VERSION ""

NS_ :

BS_:

BU_:

BO_ 3221225472 VECTOR__INDEPENDENT_SIG_MSG: 0 Vector__XXX
 SG_ station_solenoid_2_status : 0|1@1+ (1,0) [0|1] "" Vector__XXX
 SG_ station_solenoid_1_status : 0|1@1+ (1,0) [0|1] "" Vector__XXX
 SG_ gun_lock_request : 0|2@1+ (1,0) [0|3] "" Vector__XXX
 SG_ earth_life_open : 0|1@1+ (1,0) [0|1] "" Vector__XXX
 SG_ ccs_charge_detect : 0|1@1+ (1,0) [0|1] "" Vector__XXX
 SG_ string_data_no : 0|8@1+ (1,0) [0|255] "" Vector__XXX
 SG_ temp_imbalance : 0|16@1+ (0.01,-100) [-100|555.35] "" Vector__XXX
 SG_ pack_voltage_imbalance : 0|16@1+ (0.0001,0) [0|6.5535] "" Vector__XXX

BO_ 1028 afe_config_details: 8 Vector__XXX
 SG_ config_afe_gpo9 : 23|1@1+ (1,0) [0|1] "" Vector__XXX
 SG_ config_afe_gpo8 : 22|1@1+ (1,0) [0|1] "" Vector__XXX
 SG_ config_afe_gpo7 : 21|1@1+ (1,0) [0|1] "" Vector__XXX
 SG_ config_afe_gpo6 : 20|1@1+ (1,0) [0|1] "" Vector__XXX
 SG_ config_afe_gpo5 : 19|1@1+ (1,0) [0|1] "" Vector__XXX
 SG_ config_afe_gpo4 : 18|1@1+ (1,0) [0|1] "" Vector__XXX
 SG_ config_afe_gpo3 : 17|1@1+ (1,0) [0|1] "" Vector__XXX
 SG_ config_afe_gpo2 : 16|1@1+ (1,0) [0|1] "" Vector__XXX
 SG_ config_afe_gpo1 : 15|1@1+ (1,0) [0|1] "" Vector__XXX
 SG_ config_afe_gpo0 : 14|1@1+ (1,0) [0|1] "" Vector__XXX
 SG_ config_afe_mute_st : 13|1@1+ (1,0) [0|1] "" Vector__XXX
 SG_ config_afe_com_break : 12|1@1+ (1,0) [0|1] "" Vector__XXX
 SG_ config_afe_tmodchk : 11|1@1+ (1,0) [0|1] "" Vector__XXX
 SG_ config_afe_nvm_med : 10|1@1+ (1,0) [0|1] "" Vector__XXX
 SG_ config_afe_nvm_ed : 9|1@1+ (1,0) [0|1] "" Vector__XXX
 SG_ config_afe_thsd : 8|1@1+ (1,0) [0|1] "" Vector__XXX
 SG_ config_afe_supply_ov_uv : 7|1@1+ (1,0) [0|1] "" Vector__XXX
 SG_ config_afe_ed : 6|1@1+ (1,0) [0|1] "" Vector__XXX
 SG_ config_afe_ocs : 5|1@1+ (1,0) [0|1] "" Vector__XXX
 SG_ config_afe_ocf : 4|1@1+ (1,0) [0|1] "" Vector__XXX
 SG_ config_afe_cth : 1|3@1+ (1,0) [0|7] "" Vector__XXX
 SG_ config_afe_refon : 0|1@1+ (1,0) [0|1] "" Vector__XXX

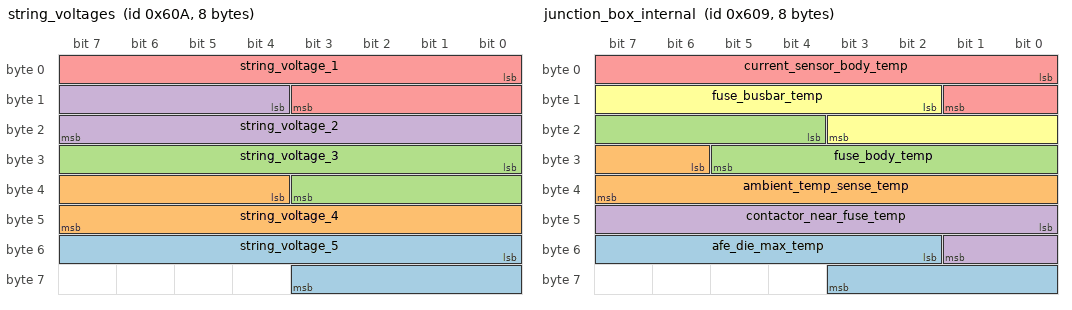
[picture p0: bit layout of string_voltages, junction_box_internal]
BO_ 1546 string_voltages: 8 Vector__XXX
 SG_ string_voltage_5 : 48|12@1+ (0.2,0) [0|819] "" Vector__XXX
 SG_ string_voltage_4 : 36|12@1+ (0.2,0) [0|819] "" Vector__XXX
 SG_ string_voltage_3 : 24|12@1+ (0.2,0) [0|819] "" Vector__XXX
 SG_ string_voltage_2 : 12|12@1+ (0.2,0) [0|819] "" Vector__XXX
 SG_ string_voltage_1 : 0|12@1+ (0.2,0) [0|819] "" Vector__XXX

BO_ 1667 subpack_unique_key: 8 Vector__XXX
 SG_ subpack_unique_key : 0|64@1+ (1,0) [0|1.84467440737096E+019] "" Vector__XXX

BO_ 1664 battery_unique_key: 8 Vector__XXX
 SG_ battery_unique_key : 0|64@1+ (1,0) [0|1.84467440737096E+019] "" Vector__XXX

BO_ 1545 junction_box_internal: 8 Vector__XXX
 SG_ afe_die_max_temp : 50|10@1+ (1,-200) [-200|823] "" Vector__XXX
 SG_ ambient_temp_sense_temp : 30|10@1+ (1,-200) [-200|823] "" Vector__XXX
 SG_ fuse_body_temp : 20|10@1+ (1,-200) [-200|823] "" Vector__XXX
 SG_ contactor_near_fuse_temp : 40|10@1+ (1,-200) [-200|823] "" Vector__XXX
 SG_ current_sensor_body_temp : 0|10@1+ (1,-200) [-200|823] "" Vector__XXX
 SG_ fuse_busbar_temp : 10|10@1+ (1,-200) [-200|823] "" Vector__XXX

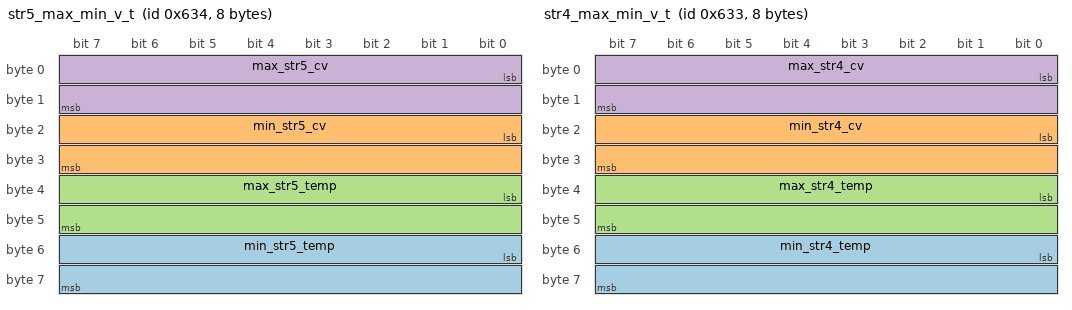
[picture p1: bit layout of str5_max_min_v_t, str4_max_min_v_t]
BO_ 1588 str5_max_min_v_t: 8 Vector__XXX
 SG_ min_str5_temp : 48|16@1+ (0.01,-100) [-100|555.35] "C" Vector__XXX
 SG_ min_str5_cv : 16|16@1+ (0.0001,0) [0|6.5535] "V" Vector__XXX
 SG_ max_str5_temp : 32|16@1+ (0.01,-100) [-100|555.35] "C" Vector__XXX
 SG_ max_str5_cv : 0|16@1+ (0.0001,0) [0|6.5535] "V" Vector__XXX

BO_ 1587 str4_max_min_v_t: 8 Vector__XXX
 SG_ min_str4_temp : 48|16@1+ (0.01,-100) [-100|555.35] "C" Vector__XXX
 SG_ min_str4_cv : 16|16@1+ (0.0001,0) [0|6.5535] "V" Vector__XXX
 SG_ max_str4_temp : 32|16@1+ (0.01,-100) [-100|555.35] "C" Vector__XXX
 SG_ max_str4_cv : 0|16@1+ (0.0001,0) [0|6.5535] "V" Vector__XXX

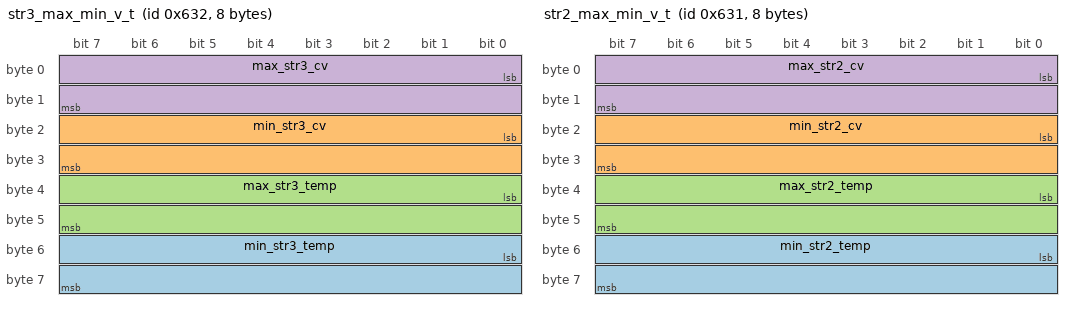
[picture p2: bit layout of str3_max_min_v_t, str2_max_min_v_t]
BO_ 1586 str3_max_min_v_t: 8 Vector__XXX
 SG_ min_str3_temp : 48|16@1+ (0.01,-100) [-100|555.35] "C" Vector__XXX
 SG_ min_str3_cv : 16|16@1+ (0.0001,0) [0|6.5535] "V" Vector__XXX
 SG_ max_str3_temp : 32|16@1+ (0.01,-100) [-100|555.35] "C" Vector__XXX
 SG_ max_str3_cv : 0|16@1+ (0.0001,0) [0|6.5535] "V" Vector__XXX

BO_ 1585 str2_max_min_v_t: 8 Vector__XXX
 SG_ min_str2_temp : 48|16@1+ (0.01,-100) [-100|555.35] "C" Vector__XXX
 SG_ min_str2_cv : 16|16@1+ (0.0001,0) [0|6.5535] "V" Vector__XXX
 SG_ max_str2_temp : 32|16@1+ (0.01,-100) [-100|555.35] "C" Vector__XXX
 SG_ max_str2_cv : 0|16@1+ (0.0001,0) [0|6.5535] "V" Vector__XXX

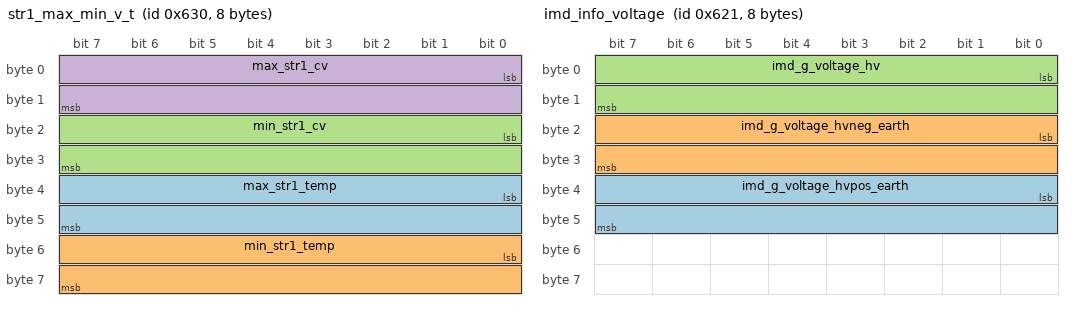
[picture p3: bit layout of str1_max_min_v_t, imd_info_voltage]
BO_ 1584 str1_max_min_v_t: 8 Vector__XXX
 SG_ max_str1_temp : 32|16@1+ (0.01,-100) [-100|555.35] "C" Vector__XXX
 SG_ min_str1_temp : 48|16@1+ (0.01,-100) [-100|555.35] "C" Vector__XXX
 SG_ min_str1_cv : 16|16@1+ (0.0001,0) [0|6.5535] "V" Vector__XXX
 SG_ max_str1_cv : 0|16@1+ (0.0001,0) [0|6.5535] "V" Vector__XXX

BO_ 1569 imd_info_voltage: 8 Vector__XXX
 SG_ imd_g_voltage_hvpos_earth : 32|16@1+ (0.1,-1000) [-1000|5553.5] "" Vector__XXX
 SG_ imd_g_voltage_hvneg_earth : 16|16@1+ (0.1,-1000) [-1000|5553.5] "" Vector__XXX
 SG_ imd_g_voltage_hv : 0|16@1+ (0.1,-1000) [-1000|5553.5] "" Vector__XXX

BO_ 1568 imd_iso_alarm_details: 8 Vector__XXX
 SG_ imd_g_warn_alarm_bit_15 : 63|1@1+ (1,0) [0|1] "" Vector__XXX
 SG_ imd_g_warn_alarm_bit_14 : 62|1@1+ (1,0) [0|1] "" Vector__XXX
 SG_ imd_g_warn_alarm_bit_13 : 61|1@1+ (1,0) [0|1] "" Vector__XXX
 SG_ imd_g_warn_alarm_bit_12 : 60|1@1+ (1,0) [0|1] "" Vector__XXX
 SG_ imd_g_warn_alarm_bit_11 : 59|1@1+ (1,0) [0|1] "" Vector__XXX
 SG_ imd_g_warn_alarm_bit_10 : 58|1@1+ (1,0) [0|1] "" Vector__XXX
 SG_ imd_g_warn_alarm_bit_09 : 57|1@1+ (1,0) [0|1] "" Vector__XXX
 SG_ imd_g_warn_alarm_bit_08 : 56|1@1+ (1,0) [0|1] "" Vector__XXX
 SG_ imd_g_warn_alarm_bit_07 : 55|1@1+ (1,0) [0|1] "" Vector__XXX
 SG_ imd_g_warn_alarm_bit_06 : 54|1@1+ (1,0) [0|1] "" Vector__XXX
 SG_ imd_g_warn_alarm_bit_05 : 53|1@1+ (1,0) [0|1] "" Vector__XXX
 SG_ imd_g_warn_alarm_bit_04 : 52|1@1+ (1,0) [0|1] "" Vector__XXX
 SG_ imd_g_warn_alarm_bit_03 : 51|1@1+ (1,0) [0|1] "" Vector__XXX
 SG_ imd_g_warn_alarm_bit_02 : 50|1@1+ (1,0) [0|1] "" Vector__XXX
 SG_ imd_g_warn_alarm_bit_01 : 49|1@1+ (1,0) [0|1] "" Vector__XXX
 SG_ imd_g_warn_alarm_bit_00 : 48|1@1+ (1,0) [0|1] "" Vector__XXX
 SG_ imd_g_iso_r_iso_original : 32|16@1+ (1,0) [0|65535] "" Vector__XXX
 SG_ imd_g_iso_r_iso_pos : 16|16@1+ (1,0) [0|65535] "" Vector__XXX
 SG_ imd_g_iso_r_iso_neg : 0|16@1+ (1,0) [0|65535] "" Vector__XXX

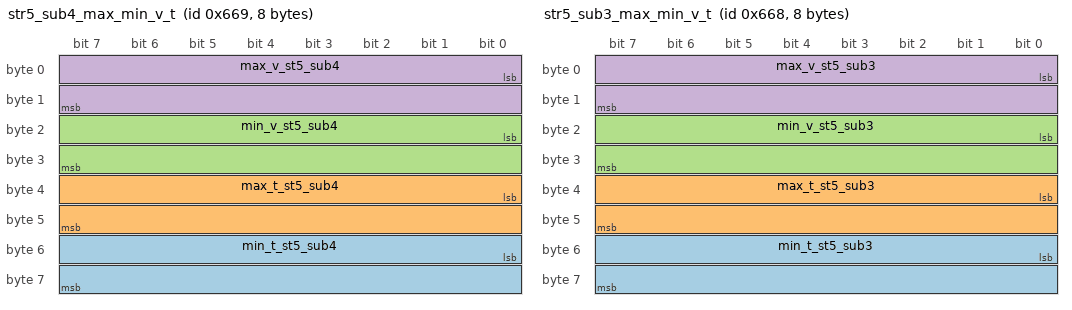
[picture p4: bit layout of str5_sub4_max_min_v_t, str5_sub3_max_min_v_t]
BO_ 1641 str5_sub4_max_min_v_t: 8 Vector__XXX
 SG_ min_t_st5_sub4 : 48|16@1+ (0.01,-100) [-100|555.35] "C" Vector__XXX
 SG_ max_t_st5_sub4 : 32|16@1+ (0.01,-100) [-100|555.35] "C" Vector__XXX
 SG_ min_v_st5_sub4 : 16|16@1+ (0.0001,0) [0|6.5535] "V" Vector__XXX
 SG_ max_v_st5_sub4 : 0|16@1+ (0.0001,0) [0|6.5535] "V" Vector__XXX

BO_ 1640 str5_sub3_max_min_v_t: 8 Vector__XXX
 SG_ min_t_st5_sub3 : 48|16@1+ (0.01,-100) [-100|555.35] "C" Vector__XXX
 SG_ max_t_st5_sub3 : 32|16@1+ (0.01,-100) [-100|555.35] "C" Vector__XXX
 SG_ min_v_st5_sub3 : 16|16@1+ (0.0001,0) [0|6.5535] "V" Vector__XXX
 SG_ max_v_st5_sub3 : 0|16@1+ (0.0001,0) [0|6.5535] "V" Vector__XXX

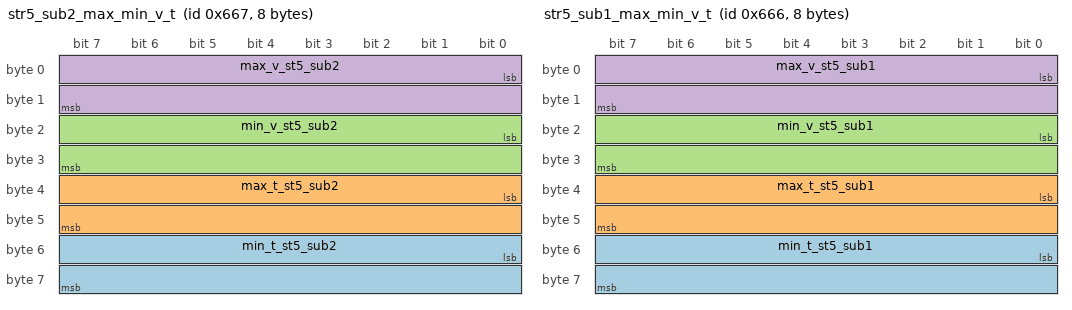
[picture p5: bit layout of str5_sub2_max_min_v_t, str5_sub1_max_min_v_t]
BO_ 1639 str5_sub2_max_min_v_t: 8 Vector__XXX
 SG_ min_t_st5_sub2 : 48|16@1+ (0.01,-100) [-100|555.35] "C" Vector__XXX
 SG_ max_t_st5_sub2 : 32|16@1+ (0.01,-100) [-100|555.35] "C" Vector__XXX
 SG_ min_v_st5_sub2 : 16|16@1+ (0.0001,0) [0|6.5535] "V" Vector__XXX
 SG_ max_v_st5_sub2 : 0|16@1+ (0.0001,0) [0|6.5535] "V" Vector__XXX

BO_ 1638 str5_sub1_max_min_v_t: 8 Vector__XXX
 SG_ min_t_st5_sub1 : 48|16@1+ (0.01,-100) [-100|555.35] "C" Vector__XXX
 SG_ max_t_st5_sub1 : 32|16@1+ (0.01,-100) [-100|555.35] "C" Vector__XXX
 SG_ min_v_st5_sub1 : 16|16@1+ (0.0001,0) [0|6.5535] "V" Vector__XXX
 SG_ max_v_st5_sub1 : 0|16@1+ (0.0001,0) [0|6.5535] "V" Vector__XXX

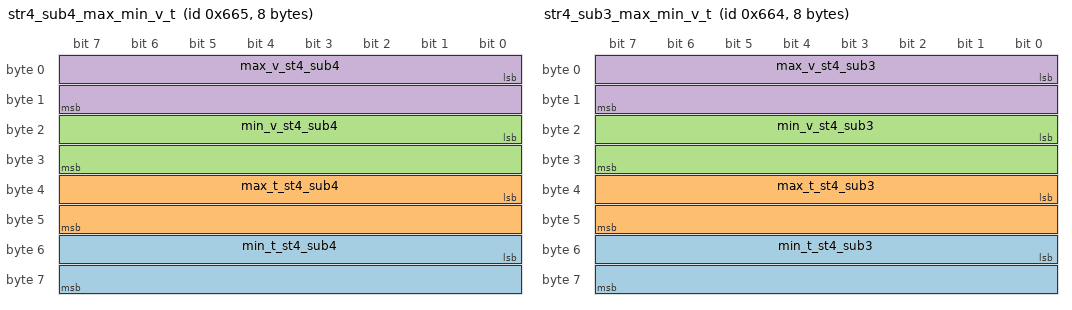
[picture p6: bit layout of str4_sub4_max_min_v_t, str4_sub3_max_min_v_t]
BO_ 1637 str4_sub4_max_min_v_t: 8 Vector__XXX
 SG_ min_t_st4_sub4 : 48|16@1+ (0.01,-100) [-100|555.35] "C" Vector__XXX
 SG_ max_t_st4_sub4 : 32|16@1+ (0.01,-100) [-100|555.35] "C" Vector__XXX
 SG_ min_v_st4_sub4 : 16|16@1+ (0.0001,0) [0|6.5535] "V" Vector__XXX
 SG_ max_v_st4_sub4 : 0|16@1+ (0.0001,0) [0|6.5535] "V" Vector__XXX

BO_ 1636 str4_sub3_max_min_v_t: 8 Vector__XXX
 SG_ min_t_st4_sub3 : 48|16@1+ (0.01,-100) [-100|555.35] "C" Vector__XXX
 SG_ max_t_st4_sub3 : 32|16@1+ (0.01,-100) [-100|555.35] "C" Vector__XXX
 SG_ min_v_st4_sub3 : 16|16@1+ (0.0001,0) [0|6.5535] "V" Vector__XXX
 SG_ max_v_st4_sub3 : 0|16@1+ (0.0001,0) [0|6.5535] "V" Vector__XXX

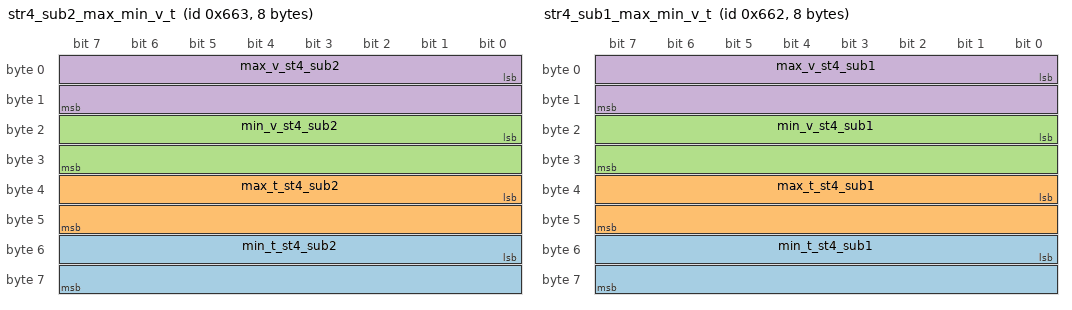
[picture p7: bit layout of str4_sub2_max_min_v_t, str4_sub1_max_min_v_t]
BO_ 1635 str4_sub2_max_min_v_t: 8 Vector__XXX
 SG_ min_t_st4_sub2 : 48|16@1+ (0.01,-100) [-100|555.35] "C" Vector__XXX
 SG_ max_t_st4_sub2 : 32|16@1+ (0.01,-100) [-100|555.35] "C" Vector__XXX
 SG_ min_v_st4_sub2 : 16|16@1+ (0.0001,0) [0|6.5535] "V" Vector__XXX
 SG_ max_v_st4_sub2 : 0|16@1+ (0.0001,0) [0|6.5535] "V" Vector__XXX

BO_ 1634 str4_sub1_max_min_v_t: 8 Vector__XXX
 SG_ min_t_st4_sub1 : 48|16@1+ (0.01,-100) [-100|555.35] "C" Vector__XXX
 SG_ max_t_st4_sub1 : 32|16@1+ (0.01,-100) [-100|555.35] "C" Vector__XXX
 SG_ min_v_st4_sub1 : 16|16@1+ (0.0001,0) [0|6.5535] "V" Vector__XXX
 SG_ max_v_st4_sub1 : 0|16@1+ (0.0001,0) [0|6.5535] "V" Vector__XXX

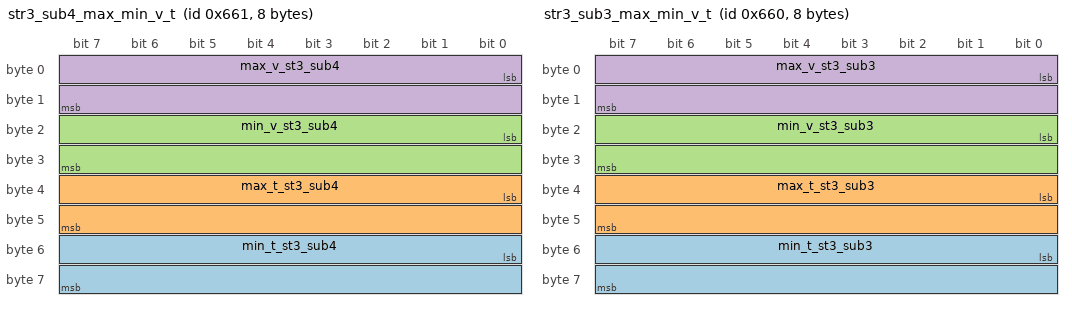
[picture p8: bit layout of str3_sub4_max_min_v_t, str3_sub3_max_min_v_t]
BO_ 1633 str3_sub4_max_min_v_t: 8 Vector__XXX
 SG_ min_t_st3_sub4 : 48|16@1+ (0.01,-100) [-100|555.35] "C" Vector__XXX
 SG_ max_t_st3_sub4 : 32|16@1+ (0.01,-100) [-100|555.35] "C" Vector__XXX
 SG_ min_v_st3_sub4 : 16|16@1+ (0.0001,0) [0|6.5535] "V" Vector__XXX
 SG_ max_v_st3_sub4 : 0|16@1+ (0.0001,0) [0|6.5535] "V" Vector__XXX

BO_ 1632 str3_sub3_max_min_v_t: 8 Vector__XXX
 SG_ min_t_st3_sub3 : 48|16@1+ (0.01,-100) [-100|555.35] "C" Vector__XXX
 SG_ max_t_st3_sub3 : 32|16@1+ (0.01,-100) [-100|555.35] "C" Vector__XXX
 SG_ min_v_st3_sub3 : 16|16@1+ (0.0001,0) [0|6.5535] "V" Vector__XXX
 SG_ max_v_st3_sub3 : 0|16@1+ (0.0001,0) [0|6.5535] "V" Vector__XXX

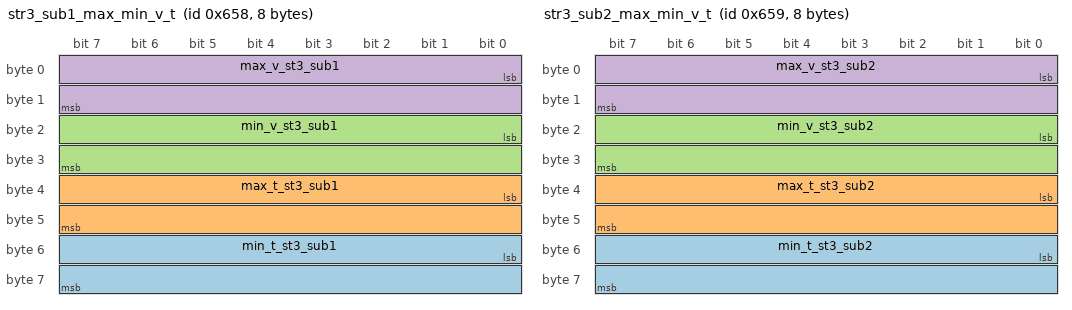
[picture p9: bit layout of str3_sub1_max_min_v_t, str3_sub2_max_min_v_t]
BO_ 1624 str3_sub1_max_min_v_t: 8 Vector__XXX
 SG_ min_t_st3_sub1 : 48|16@1+ (0.01,-100) [-100|555.35] "C" Vector__XXX
 SG_ max_t_st3_sub1 : 32|16@1+ (0.01,-100) [-100|555.35] "C" Vector__XXX
 SG_ min_v_st3_sub1 : 16|16@1+ (0.0001,0) [0|6.5535] "V" Vector__XXX
 SG_ max_v_st3_sub1 : 0|16@1+ (0.0001,0) [0|6.5535] "V" Vector__XXX

BO_ 1625 str3_sub2_max_min_v_t: 8 Vector__XXX
 SG_ min_t_st3_sub2 : 48|16@1+ (0.01,-100) [-100|555.35] "C" Vector__XXX
 SG_ max_t_st3_sub2 : 32|16@1+ (0.01,-100) [-100|555.35] "C" Vector__XXX
 SG_ min_v_st3_sub2 : 16|16@1+ (0.0001,0) [0|6.5535] "V" Vector__XXX
 SG_ max_v_st3_sub2 : 0|16@1+ (0.0001,0) [0|6.5535] "V" Vector__XXX

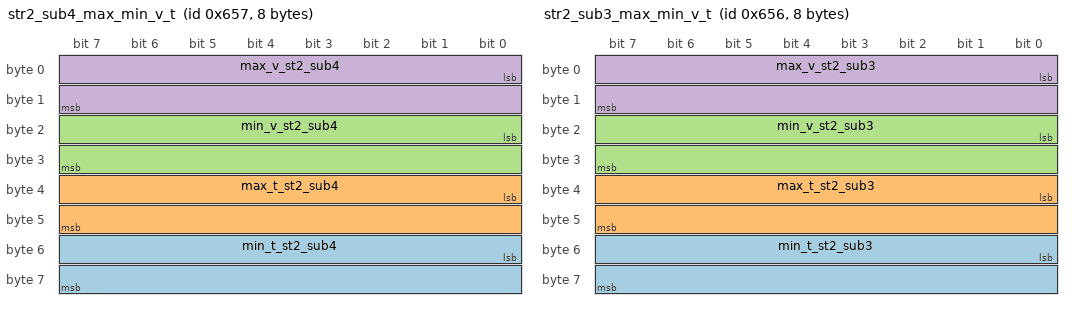
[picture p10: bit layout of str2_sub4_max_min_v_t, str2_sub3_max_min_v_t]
BO_ 1623 str2_sub4_max_min_v_t: 8 Vector__XXX
 SG_ min_t_st2_sub4 : 48|16@1+ (0.01,-100) [-100|555.35] "C" Vector__XXX
 SG_ max_t_st2_sub4 : 32|16@1+ (0.01,-100) [-100|555.35] "C" Vector__XXX
 SG_ min_v_st2_sub4 : 16|16@1+ (0.0001,0) [0|6.5535] "V" Vector__XXX
 SG_ max_v_st2_sub4 : 0|16@1+ (0.0001,0) [0|6.5535] "V" Vector__XXX

BO_ 1622 str2_sub3_max_min_v_t: 8 Vector__XXX
 SG_ min_t_st2_sub3 : 48|16@1+ (0.01,-100) [-100|555.35] "C" Vector__XXX
 SG_ max_t_st2_sub3 : 32|16@1+ (0.01,-100) [-100|555.35] "C" Vector__XXX
 SG_ min_v_st2_sub3 : 16|16@1+ (0.0001,0) [0|6.5535] "V" Vector__XXX
 SG_ max_v_st2_sub3 : 0|16@1+ (0.0001,0) [0|6.5535] "V" Vector__XXX

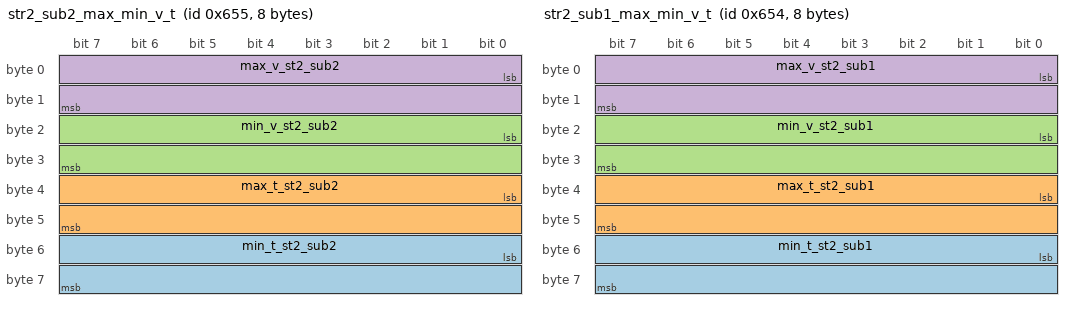
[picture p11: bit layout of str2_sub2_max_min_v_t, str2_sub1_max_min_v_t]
BO_ 1621 str2_sub2_max_min_v_t: 8 Vector__XXX
 SG_ min_t_st2_sub2 : 48|16@1+ (0.01,-100) [-100|555.35] "C" Vector__XXX
 SG_ max_t_st2_sub2 : 32|16@1+ (0.01,-100) [-100|555.35] "C" Vector__XXX
 SG_ min_v_st2_sub2 : 16|16@1+ (0.0001,0) [0|6.5535] "V" Vector__XXX
 SG_ max_v_st2_sub2 : 0|16@1+ (0.0001,0) [0|6.5535] "V" Vector__XXX

BO_ 1620 str2_sub1_max_min_v_t: 8 Vector__XXX
 SG_ min_t_st2_sub1 : 48|16@1+ (0.01,-100) [-100|555.35] "C" Vector__XXX
 SG_ max_t_st2_sub1 : 32|16@1+ (0.01,-100) [-100|555.35] "C" Vector__XXX
 SG_ min_v_st2_sub1 : 16|16@1+ (0.0001,0) [0|6.5535] "V" Vector__XXX
 SG_ max_v_st2_sub1 : 0|16@1+ (0.0001,0) [0|6.5535] "V" Vector__XXX

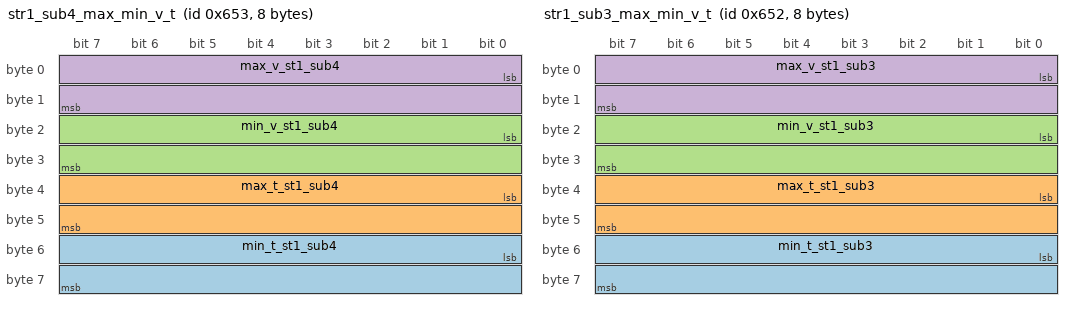
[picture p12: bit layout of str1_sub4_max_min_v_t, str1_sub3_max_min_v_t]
BO_ 1619 str1_sub4_max_min_v_t: 8 Vector__XXX
 SG_ min_t_st1_sub4 : 48|16@1+ (0.01,-100) [-100|555.35] "C" Vector__XXX
 SG_ max_t_st1_sub4 : 32|16@1+ (0.01,-100) [-100|555.35] "C" Vector__XXX
 SG_ min_v_st1_sub4 : 16|16@1+ (0.0001,0) [0|6.5535] "V" Vector__XXX
 SG_ max_v_st1_sub4 : 0|16@1+ (0.0001,0) [0|6.5535] "V" Vector__XXX

BO_ 1618 str1_sub3_max_min_v_t: 8 Vector__XXX
 SG_ min_t_st1_sub3 : 48|16@1+ (0.01,-100) [-100|555.35] "C" Vector__XXX
 SG_ max_t_st1_sub3 : 32|16@1+ (0.01,-100) [-100|555.35] "C" Vector__XXX
 SG_ min_v_st1_sub3 : 16|16@1+ (0.0001,0) [0|6.5535] "V" Vector__XXX
 SG_ max_v_st1_sub3 : 0|16@1+ (0.0001,0) [0|6.5535] "V" Vector__XXX

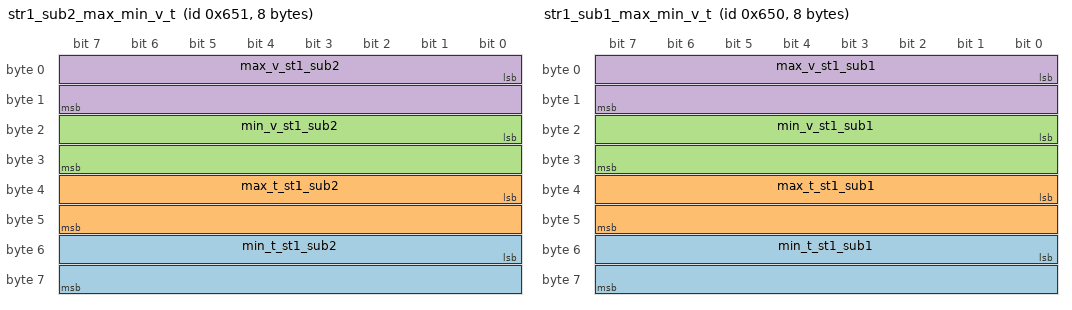
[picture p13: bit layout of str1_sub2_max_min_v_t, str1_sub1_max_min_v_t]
BO_ 1617 str1_sub2_max_min_v_t: 8 Vector__XXX
 SG_ min_t_st1_sub2 : 48|16@1+ (0.01,-100) [-100|555.35] "C" Vector__XXX
 SG_ max_t_st1_sub2 : 32|16@1+ (0.01,-100) [-100|555.35] "C" Vector__XXX
 SG_ min_v_st1_sub2 : 16|16@1+ (0.0001,0) [0|6.5535] "V" Vector__XXX
 SG_ max_v_st1_sub2 : 0|16@1+ (0.0001,0) [0|6.5535] "V" Vector__XXX

BO_ 1616 str1_sub1_max_min_v_t: 8 Vector__XXX
 SG_ min_t_st1_sub1 : 48|16@1+ (0.01,-100) [-100|555.35] "C" Vector__XXX
 SG_ max_t_st1_sub1 : 32|16@1+ (0.01,-100) [-100|555.35] "C" Vector__XXX
 SG_ min_v_st1_sub1 : 16|16@1+ (0.0001,0) [0|6.5535] "V" Vector__XXX
 SG_ max_v_st1_sub1 : 0|16@1+ (0.0001,0) [0|6.5535] "V" Vector__XXX

BO_ 336 station_heartbeat: 8 Vector__XXX
 SG_ station_unique_id : 0|32@1+ (1,0) [0|4294967295] "" Vector__XXX
 SG_ station_hw_version : 48|16@1+ (1,0) [0|65535] "" Vector__XXX
 SG_ station_fw_version : 32|16@1+ (1,0) [0|65535] "" Vector__XXX

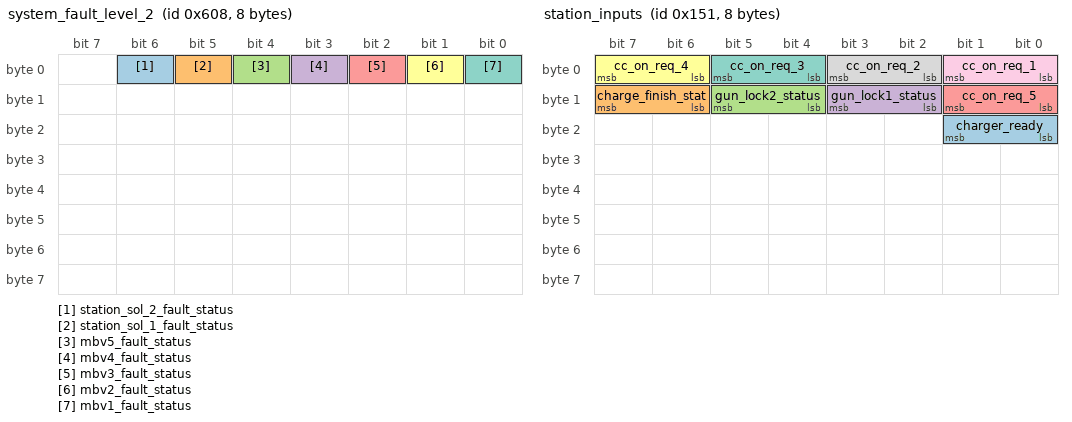
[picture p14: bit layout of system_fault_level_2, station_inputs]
BO_ 1544 system_fault_level_2: 8 Vector__XXX
 SG_ station_sol_2_fault_status : 6|1@1+ (1,0) [0|1] "" Vector__XXX
 SG_ station_sol_1_fault_status : 5|1@1+ (1,0) [0|1] "" Vector__XXX
 SG_ mbv5_fault_status : 4|1@1+ (1,0) [0|1] "" Vector__XXX
 SG_ mbv4_fault_status : 3|1@1+ (1,0) [0|1] "" Vector__XXX
 SG_ mbv3_fault_status : 2|1@1+ (1,0) [0|1] "" Vector__XXX
 SG_ mbv2_fault_status : 1|1@1+ (1,0) [0|1] "" Vector__XXX
 SG_ mbv1_fault_status : 0|1@1+ (1,0) [0|1] "" Vector__XXX

BO_ 339 override_details: 8 Vector__XXX
 SG_ override_status : 24|8@1+ (1,0) [0|0] "" Vector__XXX
 SG_ override_string_no : 16|8@1+ (1,0) [0|255] "" Vector__XXX
 SG_ override_data : 0|16@1+ (1,0) [0|65535] "" Vector__XXX

BO_ 337 station_inputs: 8 Vector__XXX
 SG_ charger_ready : 16|2@1+ (1,0) [0|3] "" Vector__XXX
 SG_ charge_finish_stat : 14|2@1+ (1,0) [0|3] "" Vector__XXX
 SG_ gun_lock2_status : 12|2@1+ (1,0) [0|3] "" Vector__XXX
 SG_ gun_lock1_status : 10|2@1+ (1,0) [0|3] "" Vector__XXX
 SG_ cc_on_req_5 : 8|2@1+ (1,0) [0|3] "" Vector__XXX
 SG_ cc_on_req_4 : 6|2@1+ (1,0) [0|3] "" Vector__XXX
 SG_ cc_on_req_3 : 4|2@1+ (1,0) [0|3] "" Vector__XXX
 SG_ cc_on_req_2 : 2|2@1+ (1,0) [0|3] "" Vector__XXX
 SG_ cc_on_req_1 : 0|2@1+ (1,0) [0|3] "" Vector__XXX

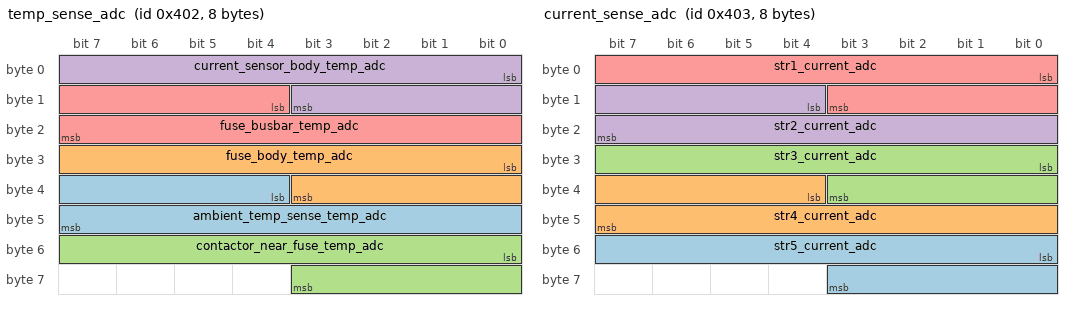
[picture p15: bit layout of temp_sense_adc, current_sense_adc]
BO_ 1026 temp_sense_adc: 8 Vector__XXX
 SG_ ambient_temp_sense_temp_adc : 36|12@1+ (1,0) [0|4095] "" Vector__XXX
 SG_ fuse_body_temp_adc : 24|12@1+ (1,0) [0|4095] "" Vector__XXX
 SG_ contactor_near_fuse_temp_adc : 48|12@1+ (1,0) [0|4095] "" Vector__XXX
 SG_ current_sensor_body_temp_adc : 0|12@1+ (1,0) [0|4095] "" Vector__XXX
 SG_ fuse_busbar_temp_adc : 12|12@1+ (1,0) [0|4095] "" Vector__XXX

BO_ 1027 current_sense_adc: 8 Vector__XXX
 SG_ str5_current_adc : 48|12@1+ (1,0) [0|4095] "" Vector__XXX
 SG_ str4_current_adc : 36|12@1+ (1,0) [0|4095] "" Vector__XXX
 SG_ str3_current_adc : 24|12@1+ (1,0) [0|4095] "" Vector__XXX
 SG_ str2_current_adc : 12|12@1+ (1,0) [0|4095] "" Vector__XXX
 SG_ str1_current_adc : 0|12@1+ (1,0) [0|4095] "" Vector__XXX

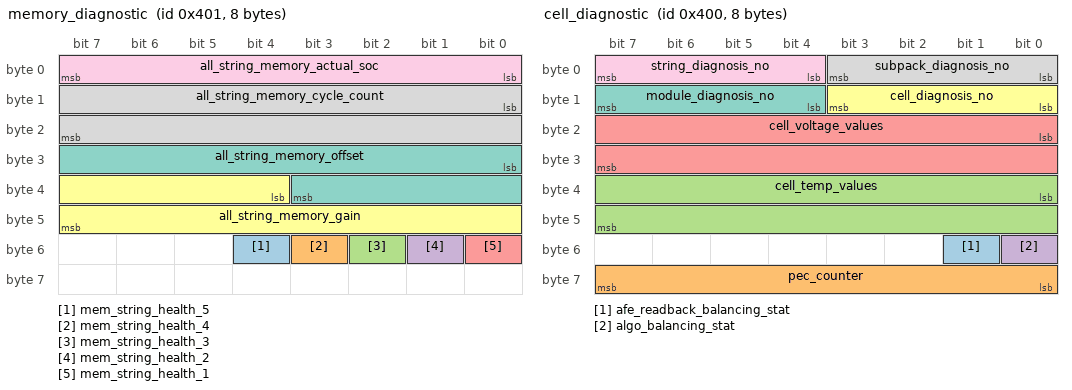
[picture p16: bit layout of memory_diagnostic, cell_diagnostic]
BO_ 1025 memory_diagnostic: 8 Vector__XXX
 SG_ mem_string_health_5 : 52|1@1+ (1,0) [0|1] "" Vector__XXX
 SG_ mem_string_health_4 : 51|1@1+ (1,0) [0|1] "" Vector__XXX
 SG_ mem_string_health_3 : 50|1@1+ (1,0) [0|1] "" Vector__XXX
 SG_ mem_string_health_2 : 49|1@1+ (1,0) [0|1] "" Vector__XXX
 SG_ mem_string_health_1 : 48|1@1+ (1,0) [0|1] "" Vector__XXX
 SG_ all_string_memory_gain : 36|12@1+ (1,0) [0|4095] "" Vector__XXX
 SG_ all_string_memory_offset : 24|12@1+ (1,0) [0|4095] "" Vector__XXX
 SG_ all_string_memory_cycle_count : 8|16@1+ (0.1,0) [0|6553.5] "" Vector__XXX
 SG_ all_string_memory_actual_soc : 0|8@1+ (0.4,0) [0|102] "" Vector__XXX

BO_ 1552 contactor_status_feed: 8 Vector__XXX
 SG_ btms_side_fluid_flow_stat : 63|1@1+ (1,0) [0|1] "" Vector__XXX
 SG_ charger_side_fluid_flow_stat : 62|1@1+ (1,0) [0|1] "" Vector__XXX
 SG_ fb_discharge_mains_negetive : 55|1@1+ (1,0) [0|1] "" Vector__XXX
 SG_ fb_discharge_mains_positive : 54|1@1+ (1,0) [0|1] "" Vector__XXX
 SG_ discharge_mains_negetive : 25|1@1+ (1,0) [0|1] "" Vector__XXX
 SG_ discharge_mains_positive : 24|1@1+ (1,0) [0|1] "" Vector__XXX
 SG_ discharge_precharge : 23|1@1+ (1,0) [0|1] "" Vector__XXX
 SG_ charge_precharge : 22|1@1+ (1,0) [0|1] "" Vector__XXX
 SG_ fb_ccs_charge_positive : 52|1@1+ (1,0) [0|1] "" Vector__XXX
 SG_ fb_ccs_charge_negetive : 53|1@1+ (1,0) [0|1] "" Vector__XXX
 SG_ ccs_charge_negetive : 21|1@1+ (1,0) [0|1] "" Vector__XXX
 SG_ ccs_charge_positive : 20|1@1+ (1,0) [0|1] "" Vector__XXX
 SG_ fb_discharge_positive_5 : 46|1@1+ (1,0) [0|1] "" Vector__XXX
 SG_ fb_discharge_positive_4 : 45|1@1+ (1,0) [0|1] "" Vector__XXX
 SG_ fb_discharge_positive_3 : 44|1@1+ (1,0) [0|1] "" Vector__XXX
 SG_ fb_discharge_positive_2 : 43|1@1+ (1,0) [0|1] "" Vector__XXX
 SG_ fb_discharge_positive_1 : 42|1@1+ (1,0) [0|1] "" Vector__XXX
 SG_ fb_discharge_negetive_5 : 51|1@1+ (1,0) [0|1] "" Vector__XXX
 SG_ fb_discharge_negetive_4 : 50|1@1+ (1,0) [0|1] "" Vector__XXX
 SG_ fb_discharge_negetive_3 : 49|1@1+ (1,0) [0|1] "" Vector__XXX
 SG_ fb_discharge_negetive_2 : 48|1@1+ (1,0) [0|1] "" Vector__XXX
 SG_ fb_discharge_negetive_1 : 47|1@1+ (1,0) [0|1] "" Vector__XXX
 SG_ fb_charge_positive_5 : 36|1@1+ (1,0) [0|1] "" Vector__XXX
 SG_ fb_charge_positive_4 : 35|1@1+ (1,0) [0|1] "" Vector__XXX
 SG_ fb_charge_positive_3 : 34|1@1+ (1,0) [0|1] "" Vector__XXX
 SG_ fb_charge_positive_2 : 33|1@1+ (1,0) [0|1] "" Vector__XXX
 SG_ fb_charge_positive_1 : 32|1@1+ (1,0) [0|1] "" Vector__XXX
 SG_ fb_charge_negetive_5 : 41|1@1+ (1,0) [0|1] "" Vector__XXX
 SG_ fb_charge_negetive_4 : 40|1@1+ (1,0) [0|1] "" Vector__XXX
 SG_ fb_charge_negetive_3 : 39|1@1+ (1,0) [0|1] "" Vector__XXX
 SG_ fb_charge_negetive_2 : 38|1@1+ (1,0) [0|1] "" Vector__XXX
 SG_ fb_charge_negetive_1 : 37|1@1+ (1,0) [0|1] "" Vector__XXX
 SG_ discharge_negetive_5 : 19|1@1+ (1,0) [0|1] "" Vector__XXX
 SG_ discharge_negetive_4 : 18|1@1+ (1,0) [0|1] "" Vector__XXX
 SG_ discharge_negetive_3 : 17|1@1+ (1,0) [0|1] "" Vector__XXX
 SG_ discharge_negetive_2 : 16|1@1+ (1,0) [0|1] "" Vector__XXX
 SG_ discharge_negetive_1 : 15|1@1+ (1,0) [0|1] "" Vector__XXX
 SG_ discharge_positive_5 : 14|1@1+ (1,0) [0|1] "" Vector__XXX
 SG_ discharge_positive_4 : 13|1@1+ (1,0) [0|1] "" Vector__XXX
 SG_ discharge_positive_3 : 12|1@1+ (1,0) [0|1] "" Vector__XXX
 SG_ discharge_positive_2 : 11|1@1+ (1,0) [0|1] "" Vector__XXX
 SG_ discharge_positive_1 : 10|1@1+ (1,0) [0|1] "" Vector__XXX
 SG_ charge_negetive_5 : 9|1@1+ (1,0) [0|1] "" Vector__XXX
 SG_ charge_negetive_4 : 8|1@1+ (1,0) [0|1] "" Vector__XXX
 SG_ charge_negetive_3 : 7|1@1+ (1,0) [0|1] "" Vector__XXX
 SG_ charge_negetive_2 : 6|1@1+ (1,0) [0|1] "" Vector__XXX
 SG_ charge_negetive_1 : 5|1@1+ (1,0) [0|1] "" Vector__XXX
 SG_ charge_positive_5 : 4|1@1+ (1,0) [0|1] "" Vector__XXX
 SG_ charge_positive_4 : 3|1@1+ (1,0) [0|1] "" Vector__XXX
 SG_ charge_positive_3 : 2|1@1+ (1,0) [0|1] "" Vector__XXX
 SG_ charge_positive_2 : 1|1@1+ (1,0) [0|1] "" Vector__XXX
 SG_ charge_positive_1 : 0|1@1+ (1,0) [0|1] "" Vector__XXX

BO_ 1024 cell_diagnostic: 8 Vector__XXX
 SG_ afe_readback_balancing_stat : 49|1@1+ (1,0) [0|0] "" Vector__XXX
 SG_ pec_counter : 56|8@1+ (1,0) [0|255] "" Vector__XXX
 SG_ cell_temp_values : 32|16@1+ (0.01,-100) [-100|555.35] "" Vector__XXX
 SG_ algo_balancing_stat : 48|1@1+ (1,0) [0|0] "" Vector__XXX
 SG_ cell_voltage_values : 16|16@1+ (0.0001,0) [0|6.5535] "" Vector__XXX
 SG_ cell_diagnosis_no : 8|4@1+ (1,0) [0|0] "" Vector__XXX
 SG_ module_diagnosis_no : 12|4@1+ (1,0) [0|0] "" Vector__XXX
 SG_ subpack_diagnosis_no : 0|4@1+ (1,0) [0|0] "" Vector__XXX
 SG_ string_diagnosis_no : 4|4@1+ (1,0) [0|0] "" Vector__XXX

BO_ 1543 system_fault_level_1: 8 Vector__XXX
 SG_ shutdown_level : 34|2@1+ (1,0) [0|3] "" Vector__XXX
 SG_ vss_level : 32|2@1+ (1,0) [0|3] "" Vector__XXX
 SG_ vls_level : 30|2@1+ (1,0) [0|3] "" Vector__XXX
 SG_ hvil_level : 28|2@1+ (1,0) [0|3] "" Vector__XXX
 SG_ roc_level : 26|2@1+ (1,0) [0|3] "" Vector__XXX
 SG_ scf_level : 24|2@1+ (1,0) [0|3] "" Vector__XXX
 SG_ tso_level : 22|2@1+ (1,0) [0|3] "" Vector__XXX
 SG_ imd_level : 20|2@1+ (1,0) [0|3] "" Vector__XXX
 SG_ doc_level : 18|2@1+ (1,0) [0|3] "" Vector__XXX
 SG_ coc_level : 16|2@1+ (1,0) [0|3] "" Vector__XXX
 SG_ dut_level : 14|2@1+ (1,0) [0|3] "" Vector__XXX
 SG_ cut_level : 12|2@1+ (1,0) [0|3] "" Vector__XXX
 SG_ dot_level : 10|2@1+ (1,0) [0|3] "" Vector__XXX
 SG_ cot_level : 8|2@1+ (1,0) [0|3] "" Vector__XXX
 SG_ puv_level : 6|2@1+ (1,0) [0|3] "" Vector__XXX
 SG_ pov_level : 4|2@1+ (1,0) [0|3] "" Vector__XXX
 SG_ cuv_level : 2|2@1+ (1,0) [0|3] "" Vector__XXX
 SG_ cov_level : 0|2@1+ (1,0) [0|3] "" Vector__XXX

BO_ 1666 bms_unique_key: 8 Vector__XXX
 SG_ bms_unique_key : 0|64@1+ (1,0) [0|1.84467440737096E+019] "" Vector__XXX

BO_ 1665 junction_box_unique_key: 8 Vector__XXX
 SG_ junction_box_unique_key : 0|64@1+ (1,0) [0|1.84467440737096E+019] "" Vector__XXX

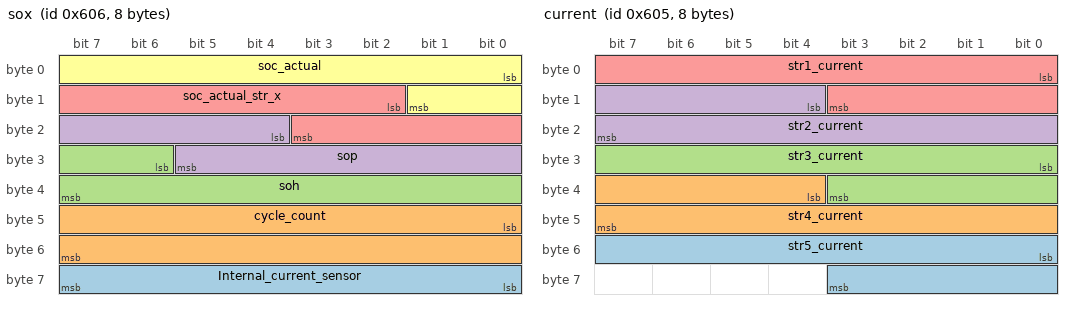
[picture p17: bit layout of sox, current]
BO_ 1542 sox: 8 Vector__XXX
 SG_ Internal_current_sensor : 56|8@1+ (0.1,0) [0|25.5] "" Vector__XXX
 SG_ cycle_count : 40|16@1+ (0.1,0) [0|6553.5] "" Vector__XXX
 SG_ soh : 30|10@1+ (0.1,0) [0|102.3] "" Vector__XXX
 SG_ sop : 20|10@1+ (0.1,0) [0|102.3] "" Vector__XXX
 SG_ soc_actual_str_x : 10|10@1+ (0.1,0) [0|102.3] "" Vector__XXX
 SG_ soc_actual : 0|10@1+ (0.1,0) [0|102.3] "" Vector__XXX

BO_ 1541 current: 8 Vector__XXX
 SG_ str5_current : 48|12@1+ (0.2,-300) [-300|519] "" Vector__XXX
 SG_ str4_current : 36|12@1+ (0.2,-300) [-300|519] "" Vector__XXX
 SG_ str3_current : 24|12@1+ (0.2,-300) [-300|519] "" Vector__XXX
 SG_ str2_current : 12|12@1+ (0.2,-300) [-300|519] "" Vector__XXX
 SG_ str1_current : 0|12@1+ (0.2,-300) [-300|519] "" Vector__XXX

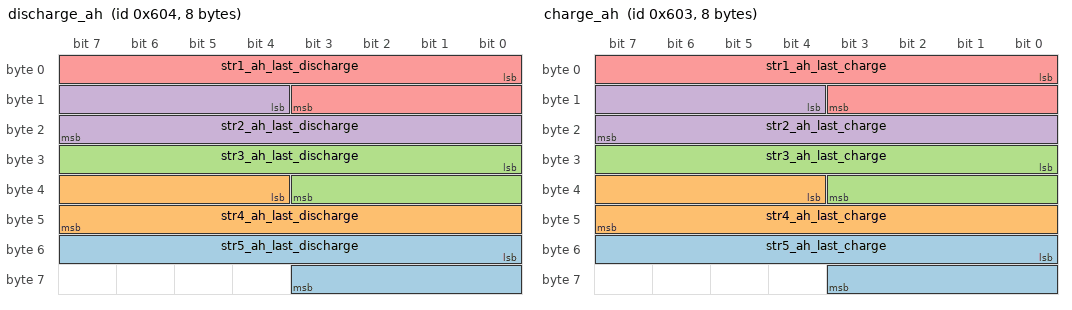
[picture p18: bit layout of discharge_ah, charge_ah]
BO_ 1540 discharge_ah: 8 Vector__XXX
 SG_ str5_ah_last_discharge : 48|12@1+ (0.1,0) [0|409.5] "" Vector__XXX
 SG_ str4_ah_last_discharge : 36|12@1+ (0.1,0) [0|409.5] "" Vector__XXX
 SG_ str3_ah_last_discharge : 24|12@1+ (0.1,0) [0|409.5] "" Vector__XXX
 SG_ str2_ah_last_discharge : 12|12@1+ (0.1,0) [0|409.5] "" Vector__XXX
 SG_ str1_ah_last_discharge : 0|12@1+ (0.1,0) [0|409.5] "" Vector__XXX

BO_ 1539 charge_ah: 8 Vector__XXX
 SG_ str5_ah_last_charge : 48|12@1+ (0.1,0) [0|409.5] "" Vector__XXX
 SG_ str4_ah_last_charge : 36|12@1+ (0.1,0) [0|409.5] "" Vector__XXX
 SG_ str3_ah_last_charge : 24|12@1+ (0.1,0) [0|409.5] "" Vector__XXX
 SG_ str2_ah_last_charge : 12|12@1+ (0.1,0) [0|409.5] "" Vector__XXX
 SG_ str1_ah_last_charge : 0|12@1+ (0.1,0) [0|409.5] "" Vector__XXX

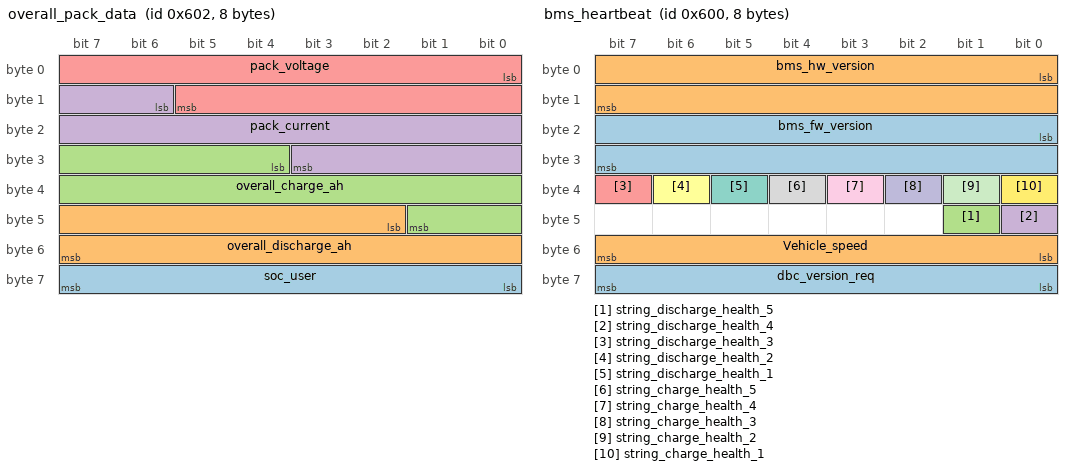
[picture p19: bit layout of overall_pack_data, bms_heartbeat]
BO_ 1538 overall_pack_data: 8 Vector__XXX
 SG_ soc_user : 56|8@1+ (0.4,0) [0|102] "" Vector__XXX
 SG_ overall_discharge_ah : 42|14@1+ (0.1,0) [0|1638.3] "" Vector__XXX
 SG_ overall_charge_ah : 28|14@1+ (0.1,0) [0|1638.3] "" Vector__XXX
 SG_ pack_current : 14|14@1+ (0.1,-250) [-250|1388.3] "" Vector__XXX
 SG_ pack_voltage : 0|14@1+ (0.1,0) [0|1638.3] "" Vector__XXX

BO_ 1537 functional_status: 8 Vector__XXX
 SG_ gun_lockfb2_status : 60|2@1+ (1,0) [0|3] "" Vector__XXX
 SG_ gun_lockfb1_status : 58|2@1+ (1,0) [0|3] "" Vector__XXX
 SG_ hvil_input_6 : 37|1@1+ (1,0) [0|1] "" Vector__XXX
 SG_ cc_on_req_5 : 27|2@1+ (1,0) [0|3] "" Vector__XXX
 SG_ cc_on_req_4 : 25|2@1+ (1,0) [0|3] "" Vector__XXX
 SG_ cc_on_req_3 : 23|2@1+ (1,0) [0|3] "" Vector__XXX
 SG_ cc_on_req_2 : 21|2@1+ (1,0) [0|3] "" Vector__XXX
 SG_ imd_fault_input : 62|1@1+ (1,0) [0|1] "" Vector__XXX
 SG_ mbv5_fb_status : 56|2@1+ (1,0) [0|3] "" Vector__XXX
 SG_ mbv4_fb_status : 54|2@1+ (1,0) [0|3] "" Vector__XXX
 SG_ mbv3_fb_status : 52|2@1+ (1,0) [0|3] "" Vector__XXX
 SG_ mbv2_fb_status : 50|2@1+ (1,0) [0|3] "" Vector__XXX
 SG_ mbv1_fb_status : 48|2@1+ (1,0) [0|3] "" Vector__XXX
 SG_ mbv5_status : 46|2@1+ (1,0) [0|3] "" Vector__XXX
 SG_ mbv4_status : 44|2@1+ (1,0) [0|3] "" Vector__XXX
 SG_ mbv3_status : 42|2@1+ (1,0) [0|3] "" Vector__XXX
 SG_ mbv2_status : 40|2@1+ (1,0) [0|3] "" Vector__XXX
 SG_ mbv1_status : 38|2@1+ (1,0) [0|3] "" Vector__XXX
 SG_ hvil_input_5 : 36|1@1+ (1,0) [0|1] "" Vector__XXX
 SG_ hvil_input_4 : 35|1@1+ (1,0) [0|1] "" Vector__XXX
 SG_ hvil_input_3 : 34|1@1+ (1,0) [0|1] "" Vector__XXX
 SG_ hvil_input_2 : 33|1@1+ (1,0) [0|1] "" Vector__XXX
 SG_ hvil_input_1 : 32|1@1+ (1,0) [0|1] "" Vector__XXX
 SG_ pp_input_2 : 31|1@1+ (1,0) [0|1] "" Vector__XXX
 SG_ pp_input_1 : 30|1@1+ (1,0) [0|1] "" Vector__XXX
 SG_ key_input : 29|1@1+ (1,0) [0|1] "" Vector__XXX
 SG_ cc_on_req_1 : 19|2@1+ (1,0) [0|3] "" Vector__XXX
 SG_ fast_charge_detect : 18|1@1+ (1,0) [0|1] "" Vector__XXX
 SG_ vcu_main_pos_relay : 16|2@1+ (1,0) [0|3] "" Vector__XXX
 SG_ vcu_hv_on_off : 14|2@1+ (1,0) [0|3] "" Vector__XXX
 SG_ discharge_allowed_status : 13|1@1+ (1,0) [0|1] "" Vector__XXX
 SG_ charge_allowed_status : 12|1@1+ (1,0) [0|1] "" Vector__XXX
 SG_ discharge_io_allow : 11|1@1+ (1,0) [0|1] "" Vector__XXX
 SG_ charge_io_allow : 10|1@1+ (1,0) [0|1] "" Vector__XXX
 SG_ charge_fault_l3 : 6|1@1+ (1,0) [0|1] "" Vector__XXX
 SG_ charge_fault_l2 : 5|1@1+ (1,0) [0|1] "" Vector__XXX
 SG_ charge_fault_l1 : 4|1@1+ (1,0) [0|1] "" Vector__XXX
 SG_ discharge_fault_l3 : 9|1@1+ (1,0) [0|1] "" Vector__XXX
 SG_ discharge_fault_l2 : 8|1@1+ (1,0) [0|1] "" Vector__XXX
 SG_ discharge_fault_l1 : 7|1@1+ (1,0) [0|1] "" Vector__XXX
 SG_ discharge_path_status : 3|1@1+ (1,0) [0|1] "" Vector__XXX
 SG_ charge_path_status : 2|1@1+ (1,0) [0|1] "" Vector__XXX
 SG_ bms_state : 0|2@1+ (1,0) [0|3] "" Vector__XXX

BO_ 1536 bms_heartbeat: 8 Vector__XXX
 SG_ dbc_version_req : 56|8@1+ (1,0) [0|0] "" Vector__XXX
 SG_ Vehicle_speed : 48|8@1+ (1,0) [0|255] "" Vector__XXX
 SG_ string_discharge_health_5 : 41|1@1+ (1,0) [0|1] "" Vector__XXX
 SG_ string_discharge_health_4 : 40|1@1+ (1,0) [0|1] "" Vector__XXX
 SG_ string_discharge_health_3 : 39|1@1+ (1,0) [0|1] "" Vector__XXX
 SG_ string_discharge_health_2 : 38|1@1+ (1,0) [0|1] "" Vector__XXX
 SG_ string_discharge_health_1 : 37|1@1+ (1,0) [0|1] "" Vector__XXX
 SG_ string_charge_health_5 : 36|1@1+ (1,0) [0|1] "" Vector__XXX
 SG_ string_charge_health_4 : 35|1@1+ (1,0) [0|1] "" Vector__XXX
 SG_ string_charge_health_3 : 34|1@1+ (1,0) [0|1] "" Vector__XXX
 SG_ string_charge_health_2 : 33|1@1+ (1,0) [0|1] "" Vector__XXX
 SG_ string_charge_health_1 : 32|1@1+ (1,0) [0|1] "" Vector__XXX
 SG_ bms_fw_version : 16|16@1+ (1,0) [0|65535] "" Vector__XXX
 SG_ bms_hw_version : 0|16@1+ (1,0) [0|65535] "" Vector__XXX

CM_ BO_ 3221225472 "This is a message for not used signals, created by Vector CANdb++ DBC OLE DB Provider.";
BA_DEF_  "BusType" STRING ;
BA_DEF_DEF_  "BusType" "CAN";
